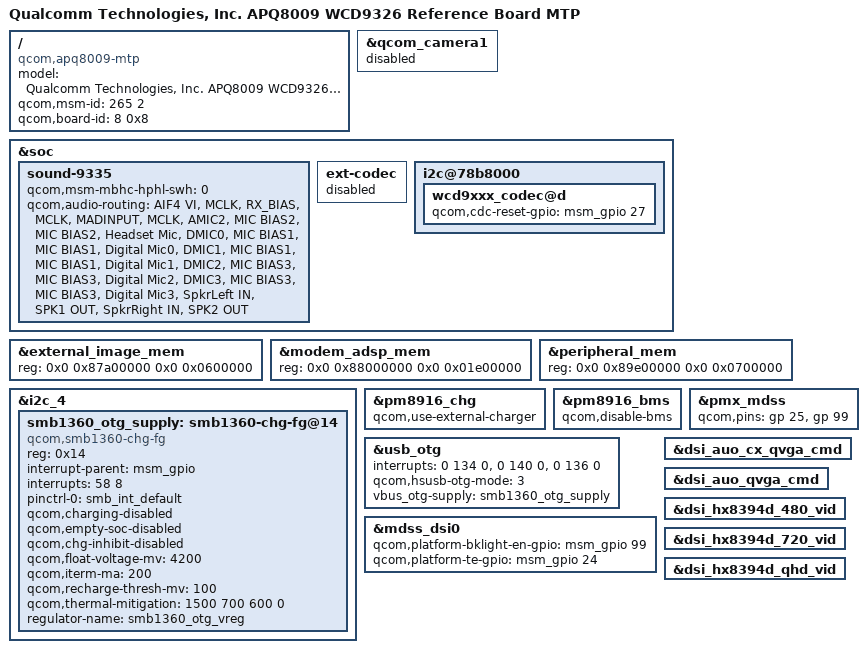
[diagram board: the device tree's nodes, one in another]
/*
 * Copyright (c) 2016, The Linux Foundation. All rights reserved.
 *
 * This program is free software; you can redistribute it and/or modify
 * it under the terms of the GNU General Public License version 2 and
 * only version 2 as published by the Free Software Foundation.
 *
 * This program is distributed in the hope that it will be useful,
 * but WITHOUT ANY WARRANTY; without even the implied warranty of
 * MERCHANTABILITY or FITNESS FOR A PARTICULAR PURPOSE.  See the
 * GNU General Public License for more details.
 */

/dts-v1/;

#include "msm8909-mtp.dtsi"
#include "msm8909-pm8916.dtsi"
#include "msm8909-pm8916-mtp.dtsi"
#include "apq8009-audio-external_codec.dtsi"

/ {
	model = "Qualcomm Technologies, Inc. APQ8009 WCD9326 Reference Board MTP";
	compatible = "qcom,apq8009-mtp", "qcom,apq8009", "qcom,mtp";
	qcom,msm-id = <265 2>;
	qcom,board-id= <8 0x8>;
};

&qcom_camera1 {
	status = "disabled";
};

&soc {
	sound-9335 {
		qcom,msm-mbhc-hphl-swh = <0>;
		qcom,audio-routing =
			"AIF4 VI", "MCLK",
			"RX_BIAS", "MCLK",
			"MADINPUT", "MCLK",
			"AMIC2", "MIC BIAS2",
			"MIC BIAS2", "Headset Mic",
			"DMIC0", "MIC BIAS1",
			"MIC BIAS1", "Digital Mic0",
			"DMIC1", "MIC BIAS1",
			"MIC BIAS1", "Digital Mic1",
			"DMIC2", "MIC BIAS3",
			"MIC BIAS3", "Digital Mic2",
			"DMIC3", "MIC BIAS3",
			"MIC BIAS3", "Digital Mic3",
			"SpkrLeft IN", "SPK1 OUT",
			"SpkrRight IN", "SPK2 OUT";
	};
        ext-codec {
                status = "disabled";
        };


	i2c@78b8000 {
		wcd9xxx_codec@d {
			qcom,cdc-reset-gpio = <&msm_gpio 27 0>;
		};
	};
};

&external_image_mem {
	reg = <0x0 0x87a00000 0x0 0x0600000>;
};

&modem_adsp_mem {
	reg = <0x0 0x88000000 0x0 0x01e00000>;
};

&peripheral_mem {
	reg = <0x0 0x89e00000 0x0 0x0700000>;
};

&i2c_4 {
	smb1360_otg_supply: smb1360-chg-fg@14 {
		compatible = "qcom,smb1360-chg-fg";
		reg = <0x14>;
		interrupt-parent = <&msm_gpio>;
		interrupts = <58 8>;
		pinctrl-names = "default";
		pinctrl-0 = <&smb_int_default>;
		qcom,charging-disabled;
		qcom,empty-soc-disabled;
		qcom,chg-inhibit-disabled;
		qcom,float-voltage-mv = <4200>;
		qcom,iterm-ma = <200>;
		qcom,recharge-thresh-mv = <100>;
		qcom,thermal-mitigation = <1500 700 600 0>;
		regulator-name = "smb1360_otg_vreg";
	};
};

&pm8916_chg {
	status = "ok";
	qcom,use-external-charger;
};

&pm8916_bms {
	status = "ok";
	qcom,disable-bms;
};

&usb_otg { interrupts = <0 134 0>,<0 140 0>,<0 136 0>;
                interrupt-names = "core_irq", "async_irq", "phy_irq";
                qcom,hsusb-otg-mode = <3>;
                vbus_otg-supply = <&smb1360_otg_supply>; };

&pmx_mdss {
        qcom,pins = <&gp 25>, <&gp 99>;
};

&mdss_dsi0 {
        qcom,platform-bklight-en-gpio = <&msm_gpio 99 0>;
        qcom,platform-te-gpio = <&msm_gpio 24 0>;
};

&dsi_auo_cx_qvga_cmd {
        /delete-property/qcom,cont-splash-enabled;
};

&dsi_auo_qvga_cmd {
        /delete-property/qcom,cont-splash-enabled;
};

&dsi_hx8394d_480_vid {
        /delete-property/qcom,cont-splash-enabled;
};

&dsi_hx8394d_720_vid {
        /delete-property/qcom,cont-splash-enabled;
};

&dsi_hx8394d_qhd_vid {
        /delete-property/qcom,cont-splash-enabled;
};
